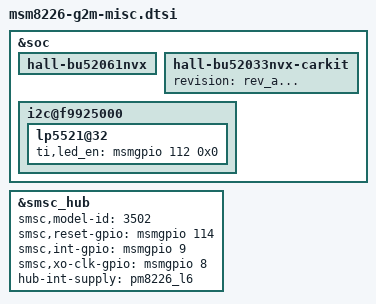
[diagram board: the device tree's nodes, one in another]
/* Copyright (c) 2012, Code Aurora Forum. All rights reserved.
 *
 * This program is free software; you can redistribute it and/or modify
 * it under the terms of the GNU General Public License version 2 and
 * only version 2 as published by the Free Software Foundation.
 *
 * This program is distributed in the hope that it will be useful,
 * but WITHOUT ANY WARRANTY; without even the implied warranty of
 * MERCHANTABILITY or FITNESS FOR A PARTICULAR PURPOSE.  See the
 * GNU General Public License for more details.
 */

&soc {
    hall-bu52061nvx {
        status = "ok";
    };

    hall-bu52033nvx-carkit {
        status = "ok";
        revision = "rev_a...";
    };

    i2c@f9925000 {
    	lp5521@32 {
    		status = "ok";
    		ti,led_en = <&msmgpio 112 0x0>;
    	};
    };
};

&smsc_hub {
	status = "ok";
	smsc,model-id = <3502>;
	smsc,reset-gpio = <&msmgpio 114 0x00>;
	smsc,int-gpio = <&msmgpio 9 0x00>;
	smsc,xo-clk-gpio = <&msmgpio 8 0x00>;
	hub-int-supply = <&pm8226_l6>;
};
